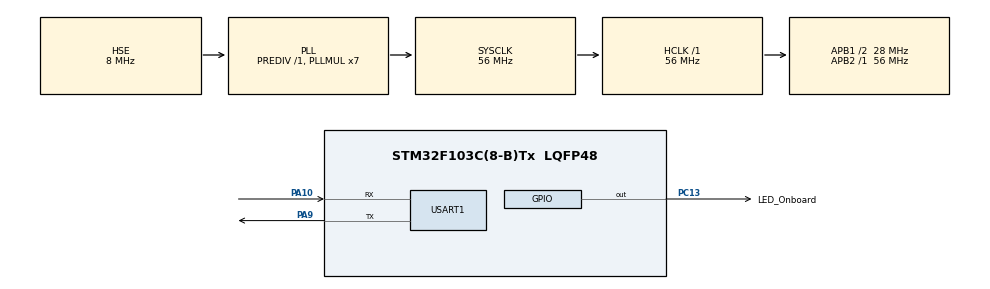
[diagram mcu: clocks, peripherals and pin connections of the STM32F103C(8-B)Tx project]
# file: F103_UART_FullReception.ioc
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Mcu.Family=STM32F1
RCC.PLLSourceVirtual=RCC_PLLSOURCE_HSE
Dma.USART1_RX.1.Instance=DMA1_Channel5
Dma.ADC1.0.Instance=DMA1_Channel1
Dma.USART1_RX.1.MemDataAlignment=DMA_MDATAALIGN_BYTE
ADC1.Rank-0\#ChannelRegularConversion=1
NVIC.DMA1_Channel5_IRQn=true\:0\:0\:false\:false\:true\:false\:true
PD1-OSC_OUT.Mode=HSE-External-Oscillator
PA10.Mode=Asynchronous
VP_ADC1_TempSens_Input.Mode=IN-TempSens
ADC1.ContinuousConvMode=ENABLE
PC13-TAMPER-RTC.Signal=GPIO_Output
PD0-OSC_IN.Signal=RCC_OSC_IN
RCC.APB1CLKDivider=RCC_HCLK_DIV2
RCC.SYSCLKSource=RCC_SYSCLKSOURCE_PLLCLK
ProjectManager.StackSize=0x400
PD1-OSC_OUT.Signal=RCC_OSC_OUT
RCC.ADCPresc=RCC_ADCPCLK2_DIV4
PA13.Signal=SYS_JTMS-SWDIO
Dma.ADC1.0.PeriphDataAlignment=DMA_PDATAALIGN_HALFWORD
PA9.Mode=Asynchronous
ProjectManager.TargetToolchain=STM32CubeIDE
Dma.ADC1.0.Mode=DMA_CIRCULAR
RCC.HCLKFreq_Value=56000000
Dma.ADC1.0.Priority=DMA_PRIORITY_LOW
RCC.APB2TimFreq_Value=56000000
PA9.Signal=USART1_TX
Dma.ADC1.0.Direction=DMA_PERIPH_TO_MEMORY
RCC.USBFreq_Value=56000000
Dma.USART1_RX.1.MemInc=DMA_MINC_ENABLE
Dma.ADC1.0.MemDataAlignment=DMA_MDATAALIGN_HALFWORD
RCC.AHBFreq_Value=56000000
PD0-OSC_IN.Mode=HSE-External-Oscillator
ADC1.Channel-0\#ChannelRegularConversion=ADC_CHANNEL_TEMPSENSOR
Dma.USART1_RX.1.PeriphDataAlignment=DMA_PDATAALIGN_BYTE
board=custom
PC13-TAMPER-RTC.GPIO_Label=LED_Onboard
RCC.PLLMUL=RCC_PLL_MUL7
RCC.APB2Freq_Value=56000000
PA14.Mode=Serial_Wire
Dma.ADC1.0.PeriphInc=DMA_PINC_DISABLE
PA13.Mode=Serial_Wire
Mcu.Name=STM32F103C(8-B)Tx
ADC1.SamplingTime-0\#ChannelRegularConversion=ADC_SAMPLETIME_239CYCLES_5
Dma.USART1_RX.1.Mode=DMA_NORMAL
RCC.SYSCLKFreq_VALUE=56000000
Mcu.Package=LQFP48
ADC1.master=1
USART1.VirtualMode=VM_ASYNC
PA10.Signal=USART1_RX
PA14.Signal=SYS_JTCK-SWCLK
Dma.ADC1.0.MemInc=DMA_MINC_ENABLE
ProjectManager.HeapSize=0x200
Dma.USART1_RX.1.PeriphInc=DMA_PINC_DISABLE
NVIC.PriorityGroup=NVIC_PRIORITYGROUP_4
ADC1.NbrOfConversionFlag=1
Dma.Request1=USART1_RX
RCC.APB1TimFreq_Value=56000000
Dma.USART1_RX.1.Direction=DMA_PERIPH_TO_MEMORY
Dma.USART1_RX.1.Priority=DMA_PRIORITY_LOW
NVIC.DMA1_Channel1_IRQn=true\:0\:0\:false\:false\:true\:false\:true
NVIC.USART1_IRQn=true\:0\:0\:false\:false\:true\:true\:true
Dma.Request0=ADC1
RCC.APB1Freq_Value=28000000

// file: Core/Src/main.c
/* USER CODE BEGIN Header */
/**
  ******************************************************************************
  * @file           : main.c
  * @brief          : Main program body
  ******************************************************************************
  * @attention
  *
  * <h2><center>&copy; Copyright (c) 2021 STMicroelectronics.
  * All rights reserved.</center></h2>
  *
  * This software component is licensed by ST under BSD 3-Clause license,
  * the "License"; You may not use this file except in compliance with the
  * License. You may obtain a copy of the License at:
  *                        opensource.org/licenses/BSD-3-Clause
  *
  ******************************************************************************
  */
/* USER CODE END Header */
#include "main.h"

/* USER CODE BEGIN Includes */
#include <string.h>
/* USER CODE END Includes */

/* USER CODE BEGIN PTD */
#define UART_RX_BufferSize 32
/* USER CODE END PTD */

ADC_HandleTypeDef hadc1;
DMA_HandleTypeDef hdma_adc1;

UART_HandleTypeDef huart1;
DMA_HandleTypeDef hdma_usart1_rx;

/* USER CODE BEGIN PV */
char UART_Rx_Buffer[UART_RX_BufferSize];

/* USER CODE END PV */

void SystemClock_Config(void);
static void MX_GPIO_Init(void);
static void MX_DMA_Init(void);
static void MX_ADC1_Init(void);
static void MX_USART1_UART_Init(void);

/* USER CODE BEGIN 0 */

void HAL_UART_RxCpltCallback(UART_HandleTypeDef *huart)
{

	if (UART_Rx_Buffer[0] == 'T')
	  {
		  HAL_UART_Transmit(&huart1, (uint8_t*)"Command Received, LED is Toggled \n", sizeof("Command Received, LED is Toggled n"), HAL_MAX_DELAY);
		  HAL_GPIO_TogglePin(LED_Onboard_GPIO_Port, LED_Onboard_Pin);
	  }
	  memset(UART_Rx_Buffer, '\0', UART_RX_BufferSize);

		if(__HAL_UART_GET_FLAG(huart, UART_FLAG_IDLE)) {									// Check if it is an "Idle Interrupt"
			__HAL_UART_CLEAR_IDLEFLAG(&huart1);
			HAL_UART_AbortReceive(&huart1);
		}

 }
}
/* USER CODE END 0 */

int main(void)
{

  /* MCU Configuration--------------------------------------------------------*/

  /* Reset of all peripherals, Initializes the Flash interface and the Systick. */
  HAL_Init();

  /* Configure the system clock */
  SystemClock_Config();

  /* Initialize all configured peripherals */
  MX_GPIO_Init();
  MX_DMA_Init();
  MX_ADC1_Init();
  MX_USART1_UART_Init();
  /* USER CODE BEGIN 2 */
  HAL_UART_Receive_DMA(&huart1, (uint8_t*) UART_Rx_Buffer, 32);
  /* USER CODE END 2 */

  /* Infinite loop */
  while (1)
  {

    /* USER CODE BEGIN 3 */

	 // HAL_Delay(500);

  }
  /* USER CODE END 3 */
}

void SystemClock_Config(void)
{
  RCC_OscInitTypeDef RCC_OscInitStruct = {0};
  RCC_ClkInitTypeDef RCC_ClkInitStruct = {0};
  RCC_PeriphCLKInitTypeDef PeriphClkInit = {0};

  /** Initializes the RCC Oscillators according to the specified parameters
  * in the RCC_OscInitTypeDef structure.
  */
  RCC_OscInitStruct.OscillatorType = RCC_OSCILLATORTYPE_HSE;
  RCC_OscInitStruct.HSEState = RCC_HSE_ON;
  RCC_OscInitStruct.HSEPredivValue = RCC_HSE_PREDIV_DIV1;
  RCC_OscInitStruct.HSIState = RCC_HSI_ON;
  RCC_OscInitStruct.PLL.PLLState = RCC_PLL_ON;
  RCC_OscInitStruct.PLL.PLLSource = RCC_PLLSOURCE_HSE;
  RCC_OscInitStruct.PLL.PLLMUL = RCC_PLL_MUL7;
  if (HAL_RCC_OscConfig(&RCC_OscInitStruct) != HAL_OK)
  {
    Error_Handler();
  }
  /** Initializes the CPU, AHB and APB buses clocks
  */
  RCC_ClkInitStruct.ClockType = RCC_CLOCKTYPE_HCLK|RCC_CLOCKTYPE_SYSCLK
                              |RCC_CLOCKTYPE_PCLK1|RCC_CLOCKTYPE_PCLK2;
  RCC_ClkInitStruct.SYSCLKSource = RCC_SYSCLKSOURCE_PLLCLK;
  RCC_ClkInitStruct.AHBCLKDivider = RCC_SYSCLK_DIV1;
  RCC_ClkInitStruct.APB1CLKDivider = RCC_HCLK_DIV2;
  RCC_ClkInitStruct.APB2CLKDivider = RCC_HCLK_DIV1;

  if (HAL_RCC_ClockConfig(&RCC_ClkInitStruct, FLASH_LATENCY_2) != HAL_OK)
  {
    Error_Handler();
  }
  PeriphClkInit.PeriphClockSelection = RCC_PERIPHCLK_ADC;
  PeriphClkInit.AdcClockSelection = RCC_ADCPCLK2_DIV4;
  if (HAL_RCCEx_PeriphCLKConfig(&PeriphClkInit) != HAL_OK)
  {
    Error_Handler();
  }
}

static void MX_ADC1_Init(void)
{

  ADC_ChannelConfTypeDef sConfig = {0};

  /** Common config
  */
  hadc1.Instance = ADC1;
  hadc1.Init.ScanConvMode = ADC_SCAN_DISABLE;
  hadc1.Init.ContinuousConvMode = ENABLE;
  hadc1.Init.DiscontinuousConvMode = DISABLE;
  hadc1.Init.ExternalTrigConv = ADC_SOFTWARE_START;
  hadc1.Init.DataAlign = ADC_DATAALIGN_RIGHT;
  hadc1.Init.NbrOfConversion = 1;
  if (HAL_ADC_Init(&hadc1) != HAL_OK)
  {
    Error_Handler();
  }
  /** Configure Regular Channel
  */
  sConfig.Channel = ADC_CHANNEL_TEMPSENSOR;
  sConfig.Rank = ADC_REGULAR_RANK_1;
  sConfig.SamplingTime = ADC_SAMPLETIME_239CYCLES_5;
  if (HAL_ADC_ConfigChannel(&hadc1, &sConfig) != HAL_OK)
  {
    Error_Handler();
  }

}

static void MX_USART1_UART_Init(void)
{

  huart1.Instance = USART1;
  huart1.Init.BaudRate = 115200;
  huart1.Init.WordLength = UART_WORDLENGTH_8B;
  huart1.Init.StopBits = UART_STOPBITS_1;
  huart1.Init.Parity = UART_PARITY_NONE;
  huart1.Init.Mode = UART_MODE_TX_RX;
  huart1.Init.HwFlowCtl = UART_HWCONTROL_NONE;
  huart1.Init.OverSampling = UART_OVERSAMPLING_16;
  if (HAL_UART_Init(&huart1) != HAL_OK)
  {
    Error_Handler();
  }

}

static void MX_DMA_Init(void)
{

  /* DMA controller clock enable */
  __HAL_RCC_DMA1_CLK_ENABLE();

  /* DMA interrupt init */
  /* DMA1_Channel1_IRQn interrupt configuration */
  HAL_NVIC_SetPriority(DMA1_Channel1_IRQn, 0, 0);
  HAL_NVIC_EnableIRQ(DMA1_Channel1_IRQn);
  /* DMA1_Channel5_IRQn interrupt configuration */
  HAL_NVIC_SetPriority(DMA1_Channel5_IRQn, 0, 0);
  HAL_NVIC_EnableIRQ(DMA1_Channel5_IRQn);

}

static void MX_GPIO_Init(void)
{
  GPIO_InitTypeDef GPIO_InitStruct = {0};

  /* GPIO Ports Clock Enable */
  __HAL_RCC_GPIOC_CLK_ENABLE();
  __HAL_RCC_GPIOD_CLK_ENABLE();
  __HAL_RCC_GPIOA_CLK_ENABLE();

  /*Configure GPIO pin Output Level */
  HAL_GPIO_WritePin(LED_Onboard_GPIO_Port, LED_Onboard_Pin, GPIO_PIN_RESET);

  /*Configure GPIO pin : LED_Onboard_Pin */
  GPIO_InitStruct.Pin = LED_Onboard_Pin;
  GPIO_InitStruct.Mode = GPIO_MODE_OUTPUT_PP;
  GPIO_InitStruct.Pull = GPIO_NOPULL;
  GPIO_InitStruct.Speed = GPIO_SPEED_FREQ_LOW;
  HAL_GPIO_Init(LED_Onboard_GPIO_Port, &GPIO_InitStruct);

}

void Error_Handler(void)
{
  __disable_irq();
  while (1)
  {
  }
}

/************************ (C) COPYRIGHT STMicroelectronics *****END OF FILE****/
